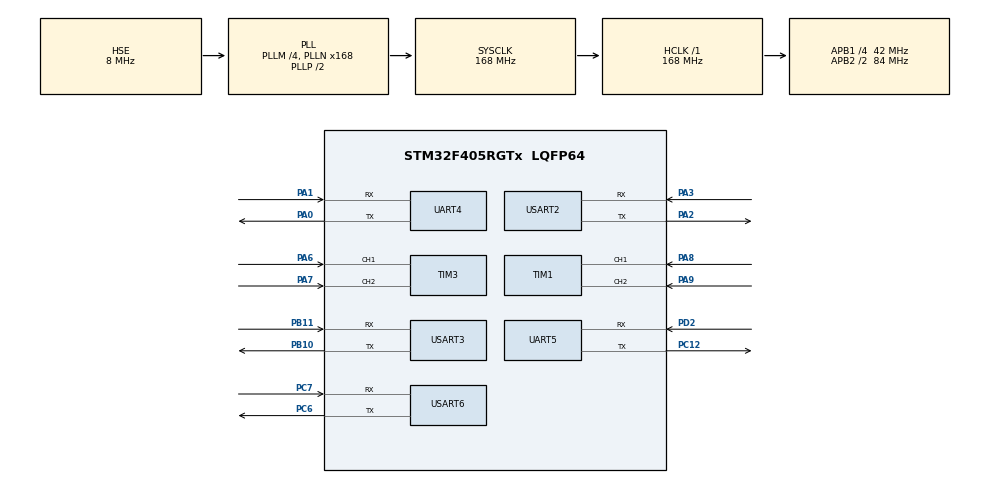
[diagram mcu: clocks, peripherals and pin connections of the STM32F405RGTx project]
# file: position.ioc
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Dma.Request0=UART4_TX
Dma.Request1=UART5_TX
Dma.Request2=USART2_TX
Dma.Request3=USART3_TX
Dma.Request4=USART6_TX
Dma.UART4_TX.0.Direction=DMA_MEMORY_TO_PERIPH
Dma.UART4_TX.0.FIFOMode=DMA_FIFOMODE_DISABLE
Dma.UART4_TX.0.Instance=DMA1_Stream4
Dma.UART4_TX.0.MemDataAlignment=DMA_MDATAALIGN_BYTE
Dma.UART4_TX.0.MemInc=DMA_MINC_ENABLE
Dma.UART4_TX.0.Mode=DMA_NORMAL
Dma.UART4_TX.0.PeriphDataAlignment=DMA_PDATAALIGN_BYTE
Dma.UART4_TX.0.PeriphInc=DMA_PINC_DISABLE
Dma.UART4_TX.0.Priority=DMA_PRIORITY_MEDIUM
Dma.UART5_TX.1.Direction=DMA_MEMORY_TO_PERIPH
Dma.UART5_TX.1.FIFOMode=DMA_FIFOMODE_DISABLE
Dma.UART5_TX.1.Instance=DMA1_Stream7
Dma.UART5_TX.1.MemDataAlignment=DMA_MDATAALIGN_BYTE
Dma.UART5_TX.1.MemInc=DMA_MINC_ENABLE
Dma.UART5_TX.1.Mode=DMA_NORMAL
Dma.UART5_TX.1.PeriphDataAlignment=DMA_PDATAALIGN_BYTE
Dma.UART5_TX.1.PeriphInc=DMA_PINC_DISABLE
Dma.UART5_TX.1.Priority=DMA_PRIORITY_MEDIUM
Dma.USART2_TX.2.Direction=DMA_MEMORY_TO_PERIPH
Dma.USART2_TX.2.FIFOMode=DMA_FIFOMODE_DISABLE
Dma.USART2_TX.2.Instance=DMA1_Stream6
Dma.USART2_TX.2.MemDataAlignment=DMA_MDATAALIGN_BYTE
Dma.USART2_TX.2.MemInc=DMA_MINC_ENABLE
Dma.USART2_TX.2.Mode=DMA_NORMAL
Dma.USART2_TX.2.PeriphDataAlignment=DMA_PDATAALIGN_BYTE
Dma.USART2_TX.2.PeriphInc=DMA_PINC_DISABLE
Dma.USART2_TX.2.Priority=DMA_PRIORITY_MEDIUM
Dma.USART3_TX.3.Direction=DMA_MEMORY_TO_PERIPH
Dma.USART3_TX.3.FIFOMode=DMA_FIFOMODE_DISABLE
Dma.USART3_TX.3.Instance=DMA1_Stream3
Dma.USART3_TX.3.MemDataAlignment=DMA_MDATAALIGN_BYTE
Dma.USART3_TX.3.MemInc=DMA_MINC_ENABLE
Dma.USART3_TX.3.Mode=DMA_NORMAL
Dma.USART3_TX.3.PeriphDataAlignment=DMA_PDATAALIGN_BYTE
Dma.USART3_TX.3.PeriphInc=DMA_PINC_DISABLE
Dma.USART3_TX.3.Priority=DMA_PRIORITY_MEDIUM
Dma.USART6_TX.4.Direction=DMA_MEMORY_TO_PERIPH
Dma.USART6_TX.4.FIFOMode=DMA_FIFOMODE_DISABLE
Dma.USART6_TX.4.Instance=DMA2_Stream6
Dma.USART6_TX.4.MemDataAlignment=DMA_MDATAALIGN_BYTE
Dma.USART6_TX.4.MemInc=DMA_MINC_ENABLE
Dma.USART6_TX.4.Mode=DMA_NORMAL
Dma.USART6_TX.4.PeriphDataAlignment=DMA_PDATAALIGN_BYTE
Dma.USART6_TX.4.PeriphInc=DMA_PINC_DISABLE
Dma.USART6_TX.4.Priority=DMA_PRIORITY_MEDIUM
FREERTOS.Tasks01=defaultTask,24,256,StartDefaultTask,Default,NULL,Dynamic,NULL,NULL
FREERTOS.configMINIMAL_STACK_SIZE=256
Mcu.Family=STM32F4
Mcu.Name=STM32F405RGTx
Mcu.Package=LQFP64
NVIC.DMA1_Stream3_IRQn=true\:5\:0\:false\:false\:true\:true\:false\:true\:true
NVIC.DMA1_Stream4_IRQn=true\:5\:0\:false\:false\:true\:true\:false\:true\:true
NVIC.DMA1_Stream6_IRQn=true\:5\:0\:false\:false\:true\:true\:false\:true\:true
NVIC.DMA1_Stream7_IRQn=true\:5\:0\:false\:false\:true\:true\:false\:true\:true
NVIC.DMA2_Stream6_IRQn=true\:5\:0\:false\:false\:true\:true\:false\:true\:true
NVIC.PriorityGroup=NVIC_PRIORITYGROUP_4
NVIC.TIM8_TRG_COM_TIM14_IRQn=true\:5\:0\:false\:false\:true\:false\:false\:true\:true
NVIC.TimeBase=TIM8_TRG_COM_TIM14_IRQn
NVIC.TimeBaseIP=TIM14
NVIC.UART4_IRQn=true\:5\:0\:true\:false\:true\:false\:true\:true\:true
NVIC.UART5_IRQn=true\:5\:0\:true\:false\:true\:false\:true\:true\:true
NVIC.USART2_IRQn=true\:4\:0\:true\:false\:true\:false\:true\:true\:true
NVIC.USART3_IRQn=true\:4\:0\:true\:false\:true\:false\:true\:true\:true
NVIC.USART6_IRQn=true\:5\:0\:false\:false\:true\:true\:true\:true\:true
PA0-WKUP.Mode=Asynchronous
PA0-WKUP.Signal=UART4_TX
PA1.Mode=Asynchronous
PA1.Signal=UART4_RX
PA13.Mode=Serial_Wire
PA13.Signal=SYS_JTMS-SWDIO
PA14.Mode=Serial_Wire
PA14.Signal=SYS_JTCK-SWCLK
PA2.Mode=Asynchronous
PA2.Signal=USART2_TX
PA3.Mode=Asynchronous
PA3.Signal=USART2_RX
PA6.Signal=S_TIM3_CH1
PA7.Signal=S_TIM3_CH2
PA8.Signal=S_TIM1_CH1
PA9.Signal=S_TIM1_CH2
PB10.Mode=Asynchronous
PB10.Signal=USART3_TX
PB11.Mode=Asynchronous
PB11.Signal=USART3_RX
PC12.Mode=Asynchronous
PC12.Signal=UART5_TX
PC6.Mode=Asynchronous
PC6.Signal=USART6_TX
PC7.Mode=Asynchronous
PC7.Signal=USART6_RX
PD2.Mode=Asynchronous
PD2.Signal=UART5_RX
PH0-OSC_IN.Mode=HSE-External-Oscillator
PH0-OSC_IN.Signal=RCC_OSC_IN
PH1-OSC_OUT.Mode=HSE-External-Oscillator
PH1-OSC_OUT.Signal=RCC_OSC_OUT
ProjectManager.HeapSize=0x200
ProjectManager.StackSize=0x400
ProjectManager.TargetToolchain=MDK-ARM V5.32
RCC.48MHZClocksFreq_Value=48000000
RCC.AHBFreq_Value=168000000
RCC.APB1CLKDivider=RCC_HCLK_DIV4
RCC.APB1Freq_Value=42000000
RCC.APB1TimFreq_Value=84000000
RCC.APB2CLKDivider=RCC_HCLK_DIV2
RCC.APB2Freq_Value=84000000
RCC.APB2TimFreq_Value=168000000
RCC.CortexFreq_Value=168000000
RCC.HCLKFreq_Value=168000000
RCC.HSE_VALUE=8000000
RCC.HSI_VALUE=16000000
RCC.LSE_VALUE=32768
RCC.PLLM=4
RCC.PLLN=168
RCC.PLLQ=7
RCC.PLLSourceVirtual=RCC_PLLSOURCE_HSE
RCC.SYSCLKFreq_VALUE=168000000
RCC.SYSCLKSource=RCC_SYSCLKSOURCE_PLLCLK
RCC.VCOOutputFreq_Value=336000000
SH.S_TIM1_CH1.0=TIM1_CH1,Encoder_Interface
SH.S_TIM1_CH2.0=TIM1_CH2,Encoder_Interface
SH.S_TIM3_CH1.0=TIM3_CH1,Encoder_Interface
SH.S_TIM3_CH2.0=TIM3_CH2,Encoder_Interface
STMicroelectronics.X-CUBE-ALGOBUILD.1.4.0.LibraryCcDSPOoLibraryJjDSPOoLibrary=true
TIM1.EncoderMode=TIM_ENCODERMODE_TI12
TIM3.EncoderMode=TIM_ENCODERMODE_TI12
UART4.VirtualMode=Asynchronous
UART5.VirtualMode=Asynchronous
USART2.VirtualMode=VM_ASYNC
USART3.VirtualMode=VM_ASYNC
USART6.VirtualMode=VM_ASYNC
VP_FREERTOS_VS_CMSIS_V2.Mode=CMSIS_V2
VP_STMicroelectronics.X-CUBE-ALGOBUILD_VS_DSPOoLibraryJjLibrary_1.4.0_1.4.0.Mode=DSPOoLibraryJjLibrary
VP_SYS_VS_tim14.Mode=TIM14
board=custom

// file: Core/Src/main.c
/* USER CODE BEGIN Header */
/**
 ******************************************************************************
 * @file           : main.c
 * @brief          : Main program body
 ******************************************************************************
 * @attention
 *
 * Copyright (c) 2025 STMicroelectronics.
 * All rights reserved.
 *
 * This software is licensed under terms that can be found in the LICENSE file
 * in the root directory of this software component.
 * If no LICENSE file comes with this software, it is provided AS-IS.
 *
 ******************************************************************************
 */
/* USER CODE END Header */
#include "main.h"
#include "cmsis_os.h"
#include "dma.h"
#include "tim.h"
#include "usart.h"
#include "gpio.h"

/* USER CODE BEGIN Includes */
#include "position_setup.h"
/* USER CODE END Includes */

void SystemClock_Config(void);
void MX_FREERTOS_Init(void);

int main(void)
{

  /* MCU Configuration--------------------------------------------------------*/

  /* Reset of all peripherals, Initializes the Flash interface and the Systick. */
  HAL_Init();

  /* Configure the system clock */
  SystemClock_Config();

  /* Initialize all configured peripherals */
  MX_GPIO_Init();
  MX_DMA_Init();
  MX_TIM1_Init();
  MX_TIM3_Init();
  MX_UART4_Init();
  MX_UART5_Init();
  MX_USART2_UART_Init();
  MX_USART3_UART_Init();
  MX_USART6_UART_Init();

  /* Init scheduler */
  osKernelInitialize();

  /* Call init function for freertos objects (in cmsis_os2.c) */

  /* Start scheduler */

  /* We should never get here as control is now taken by the scheduler */

  /* Infinite loop */
  /* USER CODE BEGIN WHILE */
  position_setup();
  while (1)
  {
    /* USER CODE END WHILE */

  }
}

void SystemClock_Config(void)
{
  RCC_OscInitTypeDef RCC_OscInitStruct = {0};
  RCC_ClkInitTypeDef RCC_ClkInitStruct = {0};

  /** Configure the main internal regulator output voltage
   */
  __HAL_RCC_PWR_CLK_ENABLE();
  __HAL_PWR_VOLTAGESCALING_CONFIG(PWR_REGULATOR_VOLTAGE_SCALE1);

  /** Initializes the RCC Oscillators according to the specified parameters
   * in the RCC_OscInitTypeDef structure.
   */
  RCC_OscInitStruct.OscillatorType = RCC_OSCILLATORTYPE_HSE;
  RCC_OscInitStruct.HSEState = RCC_HSE_ON;
  RCC_OscInitStruct.PLL.PLLState = RCC_PLL_ON;
  RCC_OscInitStruct.PLL.PLLSource = RCC_PLLSOURCE_HSE;
  RCC_OscInitStruct.PLL.PLLM = 4;
  RCC_OscInitStruct.PLL.PLLN = 168;
  RCC_OscInitStruct.PLL.PLLP = RCC_PLLP_DIV2;
  RCC_OscInitStruct.PLL.PLLQ = 7;
  if (HAL_RCC_OscConfig(&RCC_OscInitStruct) != HAL_OK)
  {
    Error_Handler();
  }

  /** Initializes the CPU, AHB and APB buses clocks
   */
  RCC_ClkInitStruct.ClockType = RCC_CLOCKTYPE_HCLK | RCC_CLOCKTYPE_SYSCLK | RCC_CLOCKTYPE_PCLK1 | RCC_CLOCKTYPE_PCLK2;
  RCC_ClkInitStruct.SYSCLKSource = RCC_SYSCLKSOURCE_PLLCLK;
  RCC_ClkInitStruct.AHBCLKDivider = RCC_SYSCLK_DIV1;
  RCC_ClkInitStruct.APB1CLKDivider = RCC_HCLK_DIV4;
  RCC_ClkInitStruct.APB2CLKDivider = RCC_HCLK_DIV2;

  if (HAL_RCC_ClockConfig(&RCC_ClkInitStruct, FLASH_LATENCY_5) != HAL_OK)
  {
    Error_Handler();
  }
}

void HAL_TIM_PeriodElapsedCallback(TIM_HandleTypeDef *htim)
{
  if (htim->Instance == TIM14)
  {
    HAL_IncTick();
  }
}

void Error_Handler(void)
{
  __disable_irq();
  while (1)
  {
  }
}
